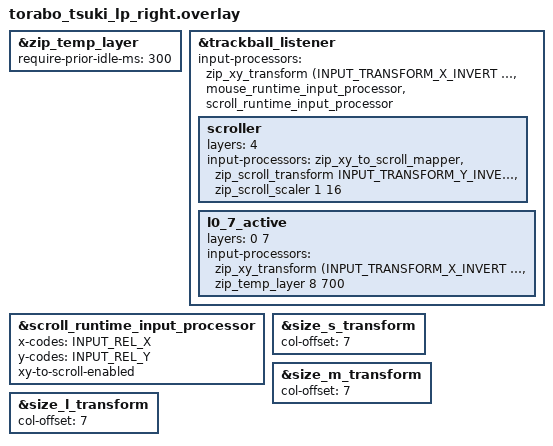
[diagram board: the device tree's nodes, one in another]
#include "torabo_tsuki_lp.dtsi"
#include <input/processors.dtsi>
#include <dt-bindings/zmk/input_transform.h>
#include <input/processors/runtime-input-processor.dtsi>

&zip_temp_layer {
    require-prior-idle-ms = <300>;
};

&trackball_listener {
    input-processors = <&zip_xy_transform (INPUT_TRANSFORM_X_INVERT | INPUT_TRANSFORM_Y_INVERT) &mouse_runtime_input_processor &scroll_runtime_input_processor>;

    scroller {
        layers = <4>;
        input-processors = <
            &zip_xy_to_scroll_mapper
            &zip_scroll_transform INPUT_TRANSFORM_Y_INVERT
            &zip_scroll_scaler 1 16
        >;
    };

    // 2. レイヤー0と7の時だけ、オートマウスを「追加」する
    l0_7_active {
        layers = <0 7>;
        input-processors = <
            &zip_xy_transform (INPUT_TRANSFORM_X_INVERT | INPUT_TRANSFORM_Y_INVERT)
            &zip_temp_layer 8 700 
        >;
    };
};

&scroll_runtime_input_processor {
        x-codes = <INPUT_REL_X>;
		y-codes = <INPUT_REL_Y>;
		xy-to-scroll-enabled;
};

&size_s_transform {
    col-offset = <7>;
};

&size_m_transform {
    col-offset = <7>;
};

&size_l_transform {
    col-offset = <7>;
};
